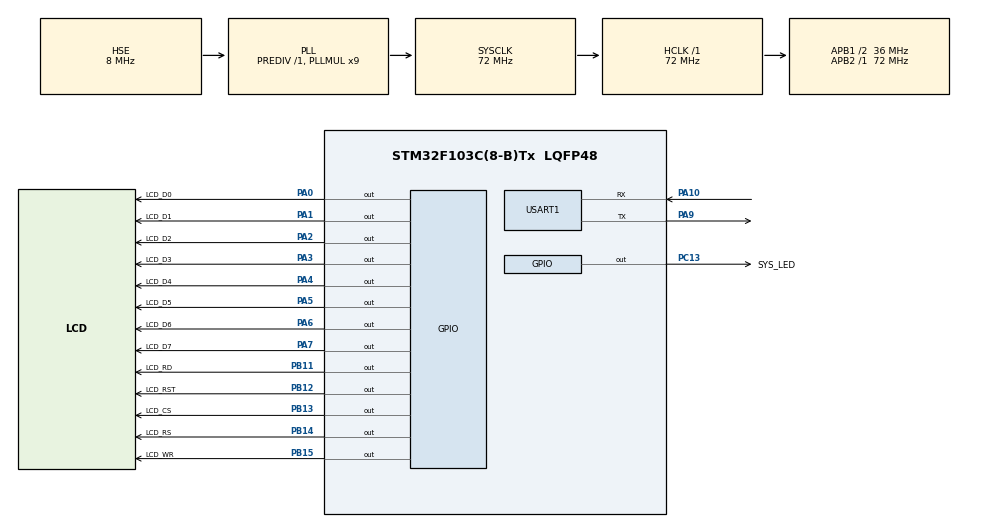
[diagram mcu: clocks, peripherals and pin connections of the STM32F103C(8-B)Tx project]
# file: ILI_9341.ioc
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Dma.Request0=USART1_RX
Dma.USART1_RX.0.Direction=DMA_PERIPH_TO_MEMORY
Dma.USART1_RX.0.Instance=DMA1_Channel5
Dma.USART1_RX.0.MemDataAlignment=DMA_MDATAALIGN_BYTE
Dma.USART1_RX.0.MemInc=DMA_MINC_ENABLE
Dma.USART1_RX.0.Mode=DMA_CIRCULAR
Dma.USART1_RX.0.PeriphDataAlignment=DMA_PDATAALIGN_BYTE
Dma.USART1_RX.0.PeriphInc=DMA_PINC_DISABLE
Dma.USART1_RX.0.Priority=DMA_PRIORITY_VERY_HIGH
Mcu.Family=STM32F1
Mcu.Name=STM32F103C(8-B)Tx
Mcu.Package=LQFP48
NVIC.DMA1_Channel5_IRQn=true\:0\:0\:false\:false\:true\:false
NVIC.PriorityGroup=NVIC_PRIORITYGROUP_4
NVIC.USART1_IRQn=true\:0\:0\:false\:true\:true\:1\:true
PA0-WKUP.GPIO_Label=LCD_D0
PA0-WKUP.Signal=GPIO_Output
PA1.GPIO_Label=LCD_D1
PA1.Signal=GPIO_Output
PA10.Mode=Asynchronous
PA10.Signal=USART1_RX
PA2.GPIO_Label=LCD_D2
PA2.Signal=GPIO_Output
PA3.GPIO_Label=LCD_D3
PA3.Signal=GPIO_Output
PA4.GPIO_Label=LCD_D4
PA4.Signal=GPIO_Output
PA5.GPIO_Label=LCD_D5
PA5.Signal=GPIO_Output
PA6.GPIO_Label=LCD_D6
PA6.Signal=GPIO_Output
PA7.GPIO_Label=LCD_D7
PA7.Signal=GPIO_Output
PA9.Mode=Asynchronous
PA9.Signal=USART1_TX
PB11.GPIO_Label=LCD_RD
PB11.Signal=GPIO_Output
PB12.GPIO_Label=LCD_RST
PB12.Signal=GPIO_Output
PB13.GPIO_Label=LCD_CS
PB13.Signal=GPIO_Output
PB14.GPIO_Label=LCD_RS
PB14.Signal=GPIO_Output
PB15.GPIO_Label=LCD_WR
PB15.Signal=GPIO_Output
PC13-TAMPER-RTC.GPIO_Label=SYS_LED
PC13-TAMPER-RTC.Signal=GPIO_Output
PD0-OSC_IN.Mode=HSE-External-Oscillator
PD0-OSC_IN.Signal=RCC_OSC_IN
PD1-OSC_OUT.Mode=HSE-External-Oscillator
PD1-OSC_OUT.Signal=RCC_OSC_OUT
ProjectManager.HeapSize=0x200
ProjectManager.StackSize=0x400
ProjectManager.TargetToolchain=Makefile
RCC.AHBFreq_Value=72000000
RCC.APB1CLKDivider=RCC_HCLK_DIV2
RCC.APB1Freq_Value=36000000
RCC.APB1TimFreq_Value=72000000
RCC.APB2Freq_Value=72000000
RCC.APB2TimFreq_Value=72000000
RCC.HCLKFreq_Value=72000000
RCC.PLLMUL=RCC_PLL_MUL9
RCC.PLLSourceVirtual=RCC_PLLSOURCE_HSE
RCC.SYSCLKFreq_VALUE=72000000
RCC.SYSCLKSource=RCC_SYSCLKSOURCE_PLLCLK
RCC.USBFreq_Value=72000000
USART1.VirtualMode=VM_ASYNC
VP_SYS_VS_ND.Mode=No_Debug
board=custom

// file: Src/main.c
/**
  ******************************************************************************
  * @file           : main.c
  * @brief          : Main program body
  ******************************************************************************
  ** This notice applies to any and all portions of this file
  * that are not between comment pairs USER CODE BEGIN and
  * USER CODE END. Other portions of this file, whether
  * inserted by the user or by software development tools
  * are owned by their respective copyright owners.
  *
  * COPYRIGHT(c) 2020 STMicroelectronics
  *
  * Redistribution and use in source and binary forms, with or without modification,
  * are permitted provided that the following conditions are met:
  *   1. Redistributions of source code must retain the above copyright notice,
  *      this list of conditions and the following disclaimer.
  *   2. Redistributions in binary form must reproduce the above copyright notice,
  *      this list of conditions and the following disclaimer in the documentation
  *      and/or other materials provided with the distribution.
  *   3. Neither the name of STMicroelectronics nor the names of its contributors
  *      may be used to endorse or promote products derived from this software
  *      without specific prior written permission.
  *
  * THIS SOFTWARE IS PROVIDED BY THE COPYRIGHT HOLDERS AND CONTRIBUTORS "AS IS"
  * AND ANY EXPRESS OR IMPLIED WARRANTIES, INCLUDING, BUT NOT LIMITED TO, THE
  * IMPLIED WARRANTIES OF MERCHANTABILITY AND FITNESS FOR A PARTICULAR PURPOSE ARE
  * DISCLAIMED. IN NO EVENT SHALL THE COPYRIGHT HOLDER OR CONTRIBUTORS BE LIABLE
  * FOR ANY DIRECT, INDIRECT, INCIDENTAL, SPECIAL, EXEMPLARY, OR CONSEQUENTIAL
  * DAMAGES (INCLUDING, BUT NOT LIMITED TO, PROCUREMENT OF SUBSTITUTE GOODS OR
  * SERVICES; LOSS OF USE, DATA, OR PROFITS; OR BUSINESS INTERRUPTION) HOWEVER
  * CAUSED AND ON ANY THEORY OF LIABILITY, WHETHER IN CONTRACT, STRICT LIABILITY,
  * OR TORT (INCLUDING NEGLIGENCE OR OTHERWISE) ARISING IN ANY WAY OUT OF THE USE
  * OF THIS SOFTWARE, EVEN IF ADVISED OF THE POSSIBILITY OF SUCH DAMAGE.
  *
  ******************************************************************************
  */
#include "main.h"
#include "stm32f1xx_hal.h"

/* USER CODE BEGIN Includes */
#include <string.h>
#include "logger.h"
#include "emulator.h"
#include "snapshot.h"
// #include "simcity.h"
#include "nether_earth2.h"
#include "arkanoids.h"
/* USER CODE END Includes */

UART_HandleTypeDef huart1;
DMA_HandleTypeDef hdma_usart1_rx;

/* USER CODE BEGIN PV */
/* Private variables ---------------------------------------------------------*/

/* USER CODE END PV */

void SystemClock_Config(void);
static void MX_GPIO_Init(void);
static void MX_DMA_Init(void);
static void MX_USART1_UART_Init(void);
static void MX_NVIC_Init(void);

/* USER CODE BEGIN PFP */
/* Private function prototypes -----------------------------------------------*/

/* USER CODE END PFP */

/* USER CODE BEGIN 0 */
  bool load;

/* USER CODE END 0 */

int main(void)
{

  /* MCU Configuration----------------------------------------------------------*/

  /* Reset of all peripherals, Initializes the Flash interface and the Systick. */
  HAL_Init();

  /* Configure the system clock */
  SystemClock_Config();

  /* Initialize all configured peripherals */
  MX_GPIO_Init();
  MX_DMA_Init();
  MX_USART1_UART_Init();

  /* Initialize interrupts */
  MX_NVIC_Init();
  /* USER CODE BEGIN 2 */
  HAL_Delay(3000);
  emulator_init();
  /* USER CODE END 2 */

  /* Infinite loop */
  while (1)
  {

  /* USER CODE BEGIN 3 */
  emulator_loop();

  if (load == true)
  {
    load = false;
    // snapshot_load(SIMCITY_Z80, sizeof(SIMCITY_Z80));
    snapshot_load(Arkanoid__1987__Imagine_Software__z80, sizeof(Arkanoid__1987__Imagine_Software__z80));
  }
  // HAL_GPIO_TogglePin(SYS_LED_GPIO_Port, SYS_LED_Pin);
  }
  /* USER CODE END 3 */

}

void SystemClock_Config(void)
{

  RCC_OscInitTypeDef RCC_OscInitStruct;
  RCC_ClkInitTypeDef RCC_ClkInitStruct;

    /**Initializes the CPU, AHB and APB busses clocks
    */
  RCC_OscInitStruct.OscillatorType = RCC_OSCILLATORTYPE_HSE;
  RCC_OscInitStruct.HSEState = RCC_HSE_ON;
  RCC_OscInitStruct.HSEPredivValue = RCC_HSE_PREDIV_DIV1;
  RCC_OscInitStruct.HSIState = RCC_HSI_ON;
  RCC_OscInitStruct.PLL.PLLState = RCC_PLL_ON;
  RCC_OscInitStruct.PLL.PLLSource = RCC_PLLSOURCE_HSE;
  RCC_OscInitStruct.PLL.PLLMUL = RCC_PLL_MUL9;
  if (HAL_RCC_OscConfig(&RCC_OscInitStruct) != HAL_OK)
  {
    _Error_Handler(__FILE__, __LINE__);
  }

    /**Initializes the CPU, AHB and APB busses clocks
    */
  RCC_ClkInitStruct.ClockType = RCC_CLOCKTYPE_HCLK|RCC_CLOCKTYPE_SYSCLK
                              |RCC_CLOCKTYPE_PCLK1|RCC_CLOCKTYPE_PCLK2;
  RCC_ClkInitStruct.SYSCLKSource = RCC_SYSCLKSOURCE_PLLCLK;
  RCC_ClkInitStruct.AHBCLKDivider = RCC_SYSCLK_DIV1;
  RCC_ClkInitStruct.APB1CLKDivider = RCC_HCLK_DIV2;
  RCC_ClkInitStruct.APB2CLKDivider = RCC_HCLK_DIV1;

  if (HAL_RCC_ClockConfig(&RCC_ClkInitStruct, FLASH_LATENCY_2) != HAL_OK)
  {
    _Error_Handler(__FILE__, __LINE__);
  }

    /**Configure the Systick interrupt time
    */
  HAL_SYSTICK_Config(HAL_RCC_GetHCLKFreq()/1000);

    /**Configure the Systick
    */
  HAL_SYSTICK_CLKSourceConfig(SYSTICK_CLKSOURCE_HCLK);

  /* SysTick_IRQn interrupt configuration */
  HAL_NVIC_SetPriority(SysTick_IRQn, 2, 0);
}

/**
  * @brief NVIC Configuration.
  * @retval None
  */
static void MX_NVIC_Init(void)
{
  /* USART1_IRQn interrupt configuration */
  HAL_NVIC_SetPriority(USART1_IRQn, 0, 0);
  HAL_NVIC_EnableIRQ(USART1_IRQn);
}

/* USART1 init function */
static void MX_USART1_UART_Init(void)
{

  huart1.Instance = USART1;
  huart1.Init.BaudRate = 115200;
  huart1.Init.WordLength = UART_WORDLENGTH_8B;
  huart1.Init.StopBits = UART_STOPBITS_1;
  huart1.Init.Parity = UART_PARITY_NONE;
  huart1.Init.Mode = UART_MODE_TX_RX;
  huart1.Init.HwFlowCtl = UART_HWCONTROL_NONE;
  huart1.Init.OverSampling = UART_OVERSAMPLING_16;
  if (HAL_UART_Init(&huart1) != HAL_OK)
  {
    _Error_Handler(__FILE__, __LINE__);
  }

}

static void MX_DMA_Init(void)
{
  /* DMA controller clock enable */
  __HAL_RCC_DMA1_CLK_ENABLE();

  /* DMA interrupt init */
  /* DMA1_Channel5_IRQn interrupt configuration */
  HAL_NVIC_SetPriority(DMA1_Channel5_IRQn, 0, 0);
  HAL_NVIC_EnableIRQ(DMA1_Channel5_IRQn);

}

/** Configure pins as
        * Analog
        * Input
        * Output
        * EVENT_OUT
        * EXTI
*/
static void MX_GPIO_Init(void)
{

  GPIO_InitTypeDef GPIO_InitStruct;

  /* GPIO Ports Clock Enable */
  __HAL_RCC_GPIOC_CLK_ENABLE();
  __HAL_RCC_GPIOD_CLK_ENABLE();
  __HAL_RCC_GPIOA_CLK_ENABLE();
  __HAL_RCC_GPIOB_CLK_ENABLE();

  /*Configure GPIO pin Output Level */
  HAL_GPIO_WritePin(SYS_LED_GPIO_Port, SYS_LED_Pin, GPIO_PIN_RESET);

  /*Configure GPIO pin Output Level */
  HAL_GPIO_WritePin(GPIOA, LCD_D0_Pin|LCD_D1_Pin|LCD_D2_Pin|LCD_D3_Pin
                          |LCD_D4_Pin|LCD_D5_Pin|LCD_D6_Pin|LCD_D7_Pin, GPIO_PIN_RESET);

  /*Configure GPIO pin Output Level */
  HAL_GPIO_WritePin(GPIOB, LCD_RD_Pin|LCD_RST_Pin|LCD_CS_Pin|LCD_RS_Pin
                          |LCD_WR_Pin, GPIO_PIN_RESET);

  /*Configure GPIO pin : SYS_LED_Pin */
  GPIO_InitStruct.Pin = SYS_LED_Pin;
  GPIO_InitStruct.Mode = GPIO_MODE_OUTPUT_PP;
  GPIO_InitStruct.Pull = GPIO_NOPULL;
  GPIO_InitStruct.Speed = GPIO_SPEED_FREQ_LOW;
  HAL_GPIO_Init(SYS_LED_GPIO_Port, &GPIO_InitStruct);

  /*Configure GPIO pins : LCD_D0_Pin LCD_D1_Pin LCD_D2_Pin LCD_D3_Pin
                           LCD_D4_Pin LCD_D5_Pin LCD_D6_Pin LCD_D7_Pin */
  GPIO_InitStruct.Pin = LCD_D0_Pin|LCD_D1_Pin|LCD_D2_Pin|LCD_D3_Pin
                          |LCD_D4_Pin|LCD_D5_Pin|LCD_D6_Pin|LCD_D7_Pin;
  GPIO_InitStruct.Mode = GPIO_MODE_OUTPUT_PP;
  GPIO_InitStruct.Pull = GPIO_NOPULL;
  GPIO_InitStruct.Speed = GPIO_SPEED_FREQ_LOW;
  HAL_GPIO_Init(GPIOA, &GPIO_InitStruct);

  /*Configure GPIO pins : LCD_RD_Pin LCD_RST_Pin LCD_CS_Pin LCD_RS_Pin
                           LCD_WR_Pin */
  GPIO_InitStruct.Pin = LCD_RD_Pin|LCD_RST_Pin|LCD_CS_Pin|LCD_RS_Pin
                          |LCD_WR_Pin;
  GPIO_InitStruct.Mode = GPIO_MODE_OUTPUT_PP;
  GPIO_InitStruct.Pull = GPIO_NOPULL;
  GPIO_InitStruct.Speed = GPIO_SPEED_FREQ_LOW;
  HAL_GPIO_Init(GPIOB, &GPIO_InitStruct);

}

void _Error_Handler(char *file, int line)
{
  while(1)
  {
  }
}

/************************ (C) COPYRIGHT STMicroelectronics *****END OF FILE****/
